# STM32H7x7_CM7 register map
File version: 1.0
CPU: CM7 r0p1, little endian, MPU, FPU, 4 interrupt priority bits
Registers are 32-bit, read-write, reset 0x0 unless marked. A register's access mark holds for its fields unless they carry their own. Offsets are from the block's base; [hi:lo] are bit positions; {n}, {i} and the like mark numbered series; 'fields as' and 'values as' point back to an identical list.

## OTG_HS_HOST — USB on the go high speed
Base 0x40040400
Same registers: OTG_FS_HOST 0x40080400
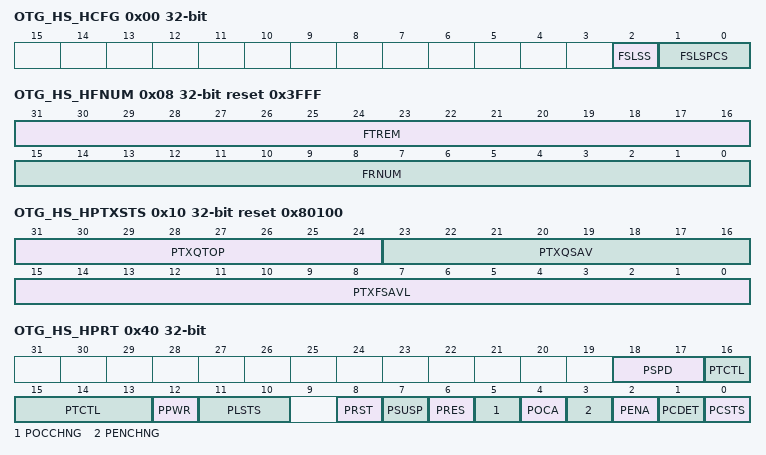
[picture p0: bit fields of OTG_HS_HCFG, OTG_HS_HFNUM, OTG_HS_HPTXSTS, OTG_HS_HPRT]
0x00 OTG_HS_HCFG access per field — OTG_HS host configuration register
  [2] FSLSS ro — FS- and LS-only support
  [1:0] FSLSPCS rw — FS/LS PHY clock select
0x04 OTG_HS_HFIR reset 0xEA60 — OTG_HS Host frame interval register
  [15:0] FRIVL — Frame interval
0x08 OTG_HS_HFNUM ro reset 0x3FFF — OTG_HS host frame number/frame time remaining register
  [31:16] FTREM — Frame time remaining
  [15:0] FRNUM — Frame number
0x10 OTG_HS_HPTXSTS access per field reset 0x80100 — OTG_HS_Host periodic transmit FIFO/queue status register
  [31:24] PTXQTOP ro — Top of the periodic transmit request queue
  [23:16] PTXQSAV ro — Periodic transmit request queue space available
  [15:0] PTXFSAVL rw — Periodic transmit data FIFO space available
0x14 OTG_HS_HAINT ro — OTG_HS Host all channels interrupt register
  [15:0] HAINT — Channel interrupts
0x18 OTG_HS_HAINTMSK — OTG_HS host all channels interrupt mask register
  [15:0] HAINTM — Channel interrupt mask
0x40 OTG_HS_HPRT access per field — OTG_HS host port control and status register
  [18:17] PSPD ro — Port speed
  [16:13] PTCTL rw — Port test control
  [12] PPWR rw — Port power
  [11:10] PLSTS ro — Port line status
  [8] PRST rw — Port reset
  [7] PSUSP rw — Port suspend
  [6] PRES rw — Port resume
  [5] POCCHNG rw — Port overcurrent change
  [4] POCA ro — Port overcurrent active
  [3] PENCHNG rw — Port enable/disable change
  [2] PENA rw — Port enable
  [1] PCDET rw — Port connect detected
  [0] PCSTS ro — Port connect status
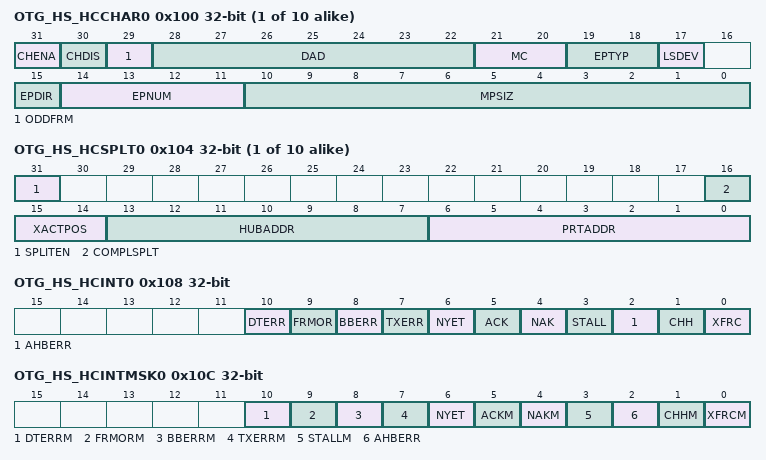
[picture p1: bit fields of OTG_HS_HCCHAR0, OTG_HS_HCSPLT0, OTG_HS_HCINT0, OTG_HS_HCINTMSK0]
{0x100+0x20*i} OTG_HS_HCCHAR{i} (i=0..9) — OTG_HS host channel-{i} characteristics register
  [31] CHENA — Channel enable
  [30] CHDIS — Channel disable
  [29] ODDFRM — Odd frame
  [28:22] DAD — Device address
  [21:20] MC — Multi Count (MC) / Error Count (EC)
  [19:18] EPTYP — Endpoint type
  [17] LSDEV — Low-speed device
  [15] EPDIR — Endpoint direction
  [14:11] EPNUM — Endpoint number
  [10:0] MPSIZ — Maximum packet size
{0x104+0x20*i} OTG_HS_HCSPLT{i} (i=0..9) — OTG_HS host channel-{i} split control register
  [31] SPLITEN — Split enable
  [16] COMPLSPLT — Do complete split
  [15:14] XACTPOS
  [13:7] HUBADDR — Hub address
  [6:0] PRTADDR — Port address
0x108 OTG_HS_HCINT0 — OTG_HS host channel-11 interrupt register
  [10] DTERR — Data toggle error
  [9] FRMOR — Frame overrun
  [8] BBERR — Babble error
  [7] TXERR — Transaction error
  [6] NYET — Response received interrupt
  [5] ACK — ACK response received/transmitted interrupt
  [4] NAK — NAK response received interrupt
  [3] STALL — STALL response received interrupt
  [2] AHBERR — AHB error
  [1] CHH — Channel halted
  [0] XFRC — Transfer completed
0x10C OTG_HS_HCINTMSK0 — OTG_HS host channel-11 interrupt mask register
  [10] DTERRM — Data toggle error mask
  [9] FRMORM — Frame overrun mask
  [8] BBERRM — Babble error mask
  [7] TXERRM — Transaction error mask
  [6] NYET — response received interrupt mask
  [5] ACKM — ACK response received/transmitted interrupt mask
  [4] NAKM — NAK response received interrupt mask
  [3] STALLM — STALL response received interrupt mask
  [2] AHBERR — AHB error
  [1] CHHM — Channel halted mask
  [0] XFRCM — Transfer completed mask
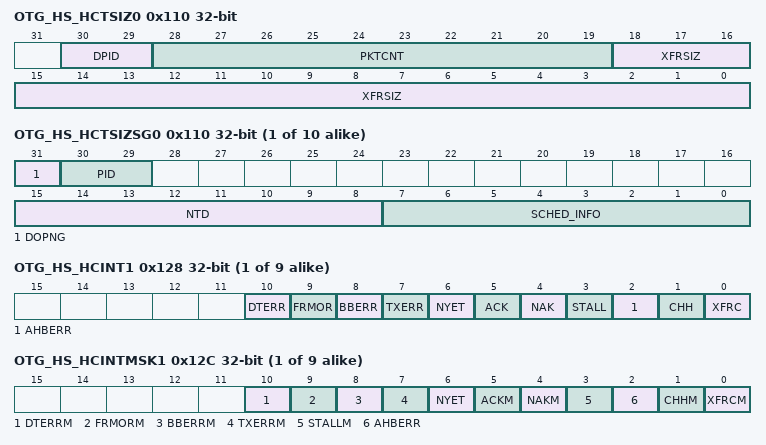
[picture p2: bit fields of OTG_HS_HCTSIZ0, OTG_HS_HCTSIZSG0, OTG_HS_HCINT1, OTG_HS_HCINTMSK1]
0x110 OTG_HS_HCTSIZ0 — OTG_HS host channel-11 transfer size register
  [30:29] DPID — Data PID
  [28:19] PKTCNT — Packet count
  [18:0] XFRSIZ — Transfer size
{0x110+0x20*i} OTG_HS_HCTSIZSG{i} (alternate view of OTG_HS_HCTSIZ{i}) (i=0..9) — OTG host channel x transfer size register
  [31] DOPNG — Do ping
  [30:29] PID
  [15:8] NTD — Number of transfer descriptors
  [7:0] SCHED_INFO — Schedule information
{0x114+0x20*i} OTG_HS_HCDMA{i} (i=0..9) — OTG_HS host channel-{i} DMA address register
  [31:0] DMAADDR — DMA address
{0x114+0x20*i} OTG_HS_HCDMASG{i} (alternate view of OTG_HS_HCDMA{i}) (i=0..9) — OTG host channel x DMA address in scatter/gather DMA register
  [31:3] DMASG — DMA scatter/gather information
{0x108+0x20*i} OTG_HS_HCINT{i} (i=1..9) — OTG_HS host channel-{i} interrupt register
  fields as OTG_HS_HCINT0
{0x10C+0x20*i} OTG_HS_HCINTMSK{i} (i=1..9) — OTG_HS host channel-{i} interrupt mask register
  fields as OTG_HS_HCINTMSK0
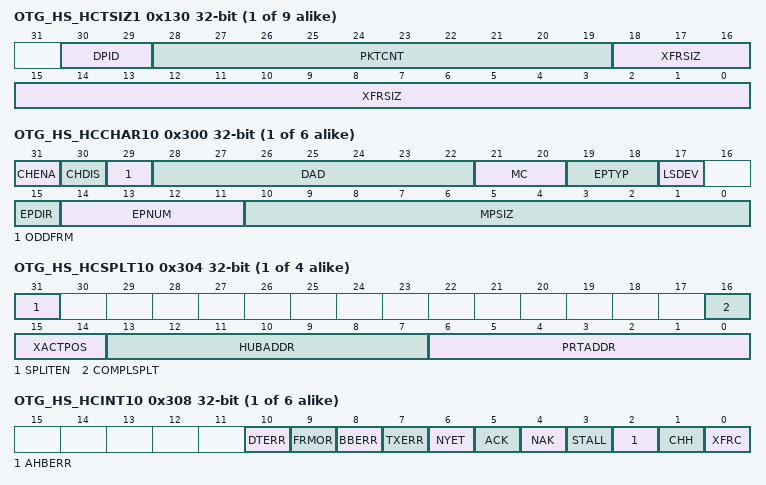
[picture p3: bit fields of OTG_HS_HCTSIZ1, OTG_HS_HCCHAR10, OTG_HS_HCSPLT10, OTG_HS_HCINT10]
{0x110+0x20*i} OTG_HS_HCTSIZ{i} (i=1..9) — OTG_HS host channel-{i} transfer size register
  fields as OTG_HS_HCTSIZ0
{0x1C0+0x20*i} OTG_HS_HCCHAR{i} (i=10..15) — OTG_HS host channel-{i} characteristics register
  fields as OTG_HS_HCCHAR0
{0x1C4+0x20*i} OTG_HS_HCSPLT{i} (i=10..13) — OTG_HS host channel-{i} split control register
  fields as OTG_HS_HCSPLT0
{0x1C8+0x20*i} OTG_HS_HCINT{i} (i=10..15) — OTG_HS host channel-{i} interrupt register
  fields as OTG_HS_HCINT0
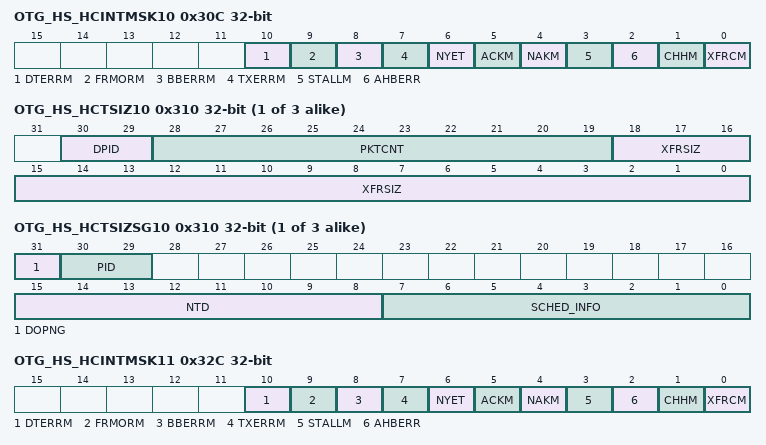
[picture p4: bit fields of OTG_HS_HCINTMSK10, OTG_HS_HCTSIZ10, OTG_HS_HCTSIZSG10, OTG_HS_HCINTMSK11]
0x30C OTG_HS_HCINTMSK10 — OTG_HS host channel-10 interrupt mask register
  fields as OTG_HS_HCINTMSK0
{0x1D0+0x20*i} OTG_HS_HCTSIZ{i} (i=10..12) — OTG_HS host channel-{i} transfer size register
  fields as OTG_HS_HCTSIZ0
{0x1D0+0x20*i} OTG_HS_HCTSIZSG{i} (alternate view of OTG_HS_HCTSIZ{i}) (i=10..12) — OTG host channel x transfer size register
  fields as OTG_HS_HCTSIZSG0
{0x1D4+0x20*i} OTG_HS_HCDMA{i} (i=10..15) — OTG_HS host channel-{i} DMA address register
  [31:0] DMAADDR — DMA address
{0x1D4+0x20*i} OTG_HS_HCDMASG{i} (alternate view of OTG_HS_HCDMA{i}) (i=10..15) — OTG host channel x DMA address in scatter/gather DMA register
  [31:3] DMASG — DMA scatter/gather information
0x32C OTG_HS_HCINTMSK11 — OTG_HS host channel-11 interrupt mask register
  fields as OTG_HS_HCINTMSK0
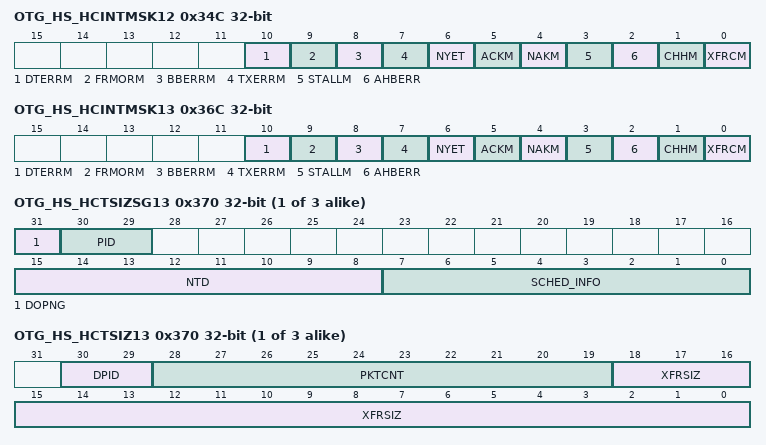
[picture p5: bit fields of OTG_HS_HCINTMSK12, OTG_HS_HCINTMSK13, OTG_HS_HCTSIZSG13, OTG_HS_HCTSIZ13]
0x34C OTG_HS_HCINTMSK12 — OTG_HS host channel-12 interrupt mask register
  [10] DTERRM — Data toggle error mask
  [9] FRMORM — Frame overrun mask
  [8] BBERRM — Babble error
  [7] TXERRM — Transaction error
  [6] NYET — Response received interrupt
  [5] ACKM — ACK response received/transmitted interrupt mask
  [4] NAKM — NAK response received interrupt mask
  [3] STALLM — STALL response received interrupt mask
  [2] AHBERR — AHB error
  [1] CHHM — Channel halted mask
  [0] XFRCM — Transfer completed mask
0x36C OTG_HS_HCINTMSK13 — OTG_HS host channel-13 interrupt mask register
  [10] DTERRM — Data toggle error mask
  [9] FRMORM — Frame overrun mask
  [8] BBERRM — Babble error
  [7] TXERRM — Transaction error
  [6] NYET — Response received interrupt
  [5] ACKM — ACK response received/transmitted interrupt mask
  [4] NAKM — NAK response received interrupt mask
  [3] STALLM — STALLM response received interrupt mask
  [2] AHBERR — AHB error
  [1] CHHM — Channel halted mask
  [0] XFRCM — Transfer completed mask
{0x1D0+0x20*i} OTG_HS_HCTSIZSG{i} (i=13..15) — OTG host channel x transfer size register
  fields as OTG_HS_HCTSIZSG0
{0x1D0+0x20*i} OTG_HS_HCTSIZ{i} (alternate view of OTG_HS_HCTSIZSG{i}) (i=13..15) — OTG_HS host channel-{i} transfer size register
  fields as OTG_HS_HCTSIZ0
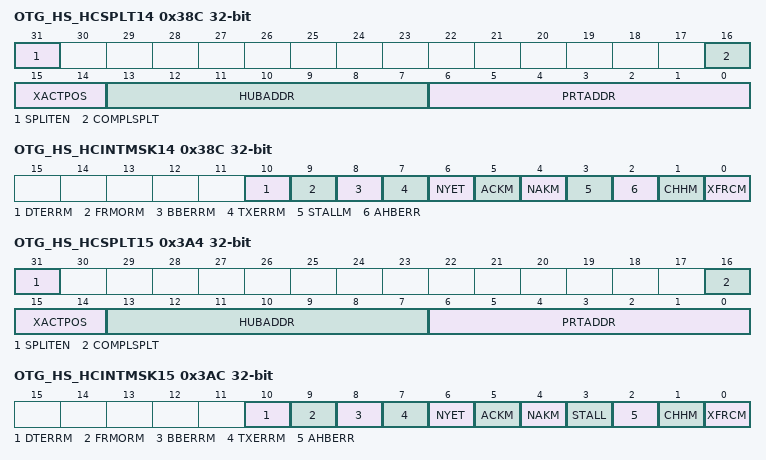
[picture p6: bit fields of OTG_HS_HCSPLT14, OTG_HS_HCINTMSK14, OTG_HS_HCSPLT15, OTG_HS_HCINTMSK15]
0x38C OTG_HS_HCSPLT14 — OTG_HS host channel-14 split control register
  fields as OTG_HS_HCSPLT0
0x38C OTG_HS_HCINTMSK14 (alternate view of OTG_HS_HCSPLT14) — OTG_HS host channel-14 interrupt mask register
  [10] DTERRM — Data toggle error mask
  [9] FRMORM — Frame overrun mask
  [8] BBERRM — Babble error
  [7] TXERRM — Transaction error
  [6] NYET — Response received interrupt
  [5] ACKM — ACKM response received/transmitted interrupt mask
  [4] NAKM — NAKM response received interrupt mask
  [3] STALLM — STALL response received interrupt mask
  [2] AHBERR — AHB error
  [1] CHHM — Channel halted mask
  [0] XFRCM — Transfer completed mask
0x3A4 OTG_HS_HCSPLT15 — OTG_HS host channel-15 split control register
  fields as OTG_HS_HCSPLT0
0x3AC OTG_HS_HCINTMSK15 — OTG_HS host channel-15 interrupt mask register
  [10] DTERRM — Data toggle error mask
  [9] FRMORM — Frame overrun mask
  [8] BBERRM — Babble error
  [7] TXERRM — Transaction error
  [6] NYET — Response received interrupt
  [5] ACKM — ACK response received/transmitted interrupt mask
  [4] NAKM — NAK response received interrupt mask
  [3] STALL — STALL response received interrupt mask
  [2] AHBERR — AHB error
  [1] CHHM — Channel halted mask
  [0] XFRCM — Transfer completed mask
